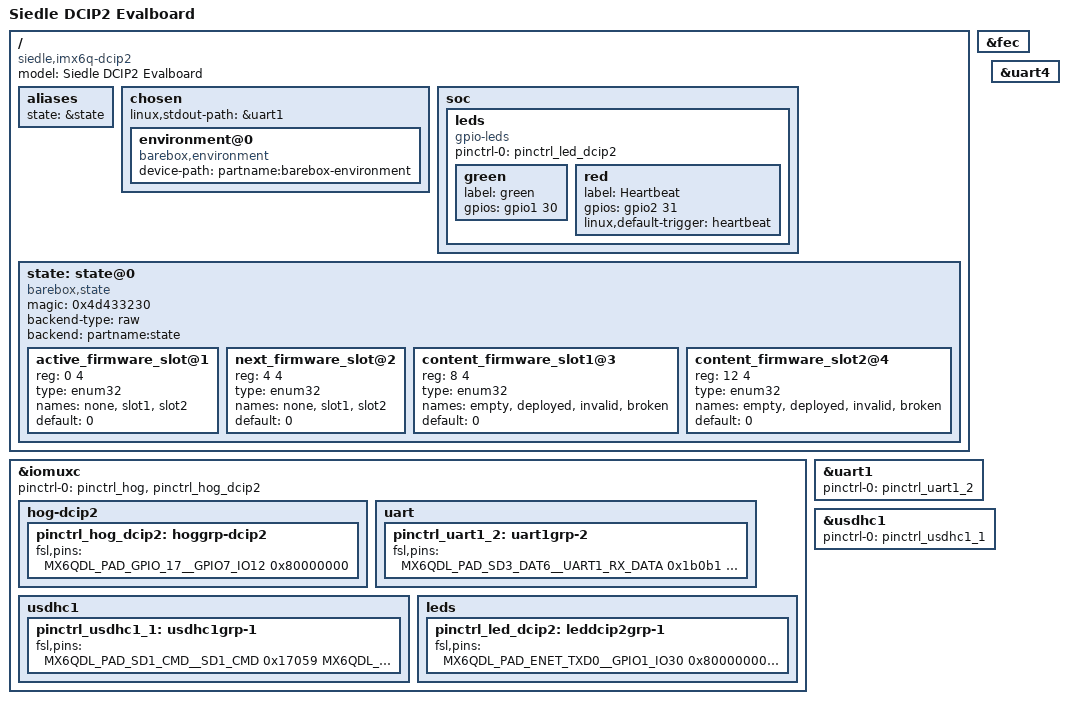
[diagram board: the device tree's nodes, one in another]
/*
 * Copyright 2013 Christian Hemp, Phytec Messtechnik GmbH
 *
 * The code contained herein is licensed under the GNU General Public
 * License. You may obtain a copy of the GNU General Public License
 * Version 2 or later at the following locations:
 *
 * http://www.opensource.org/licenses/gpl-license.html
 * http://www.gnu.org/copyleft/gpl.html
 */

/dts-v1/;
#include "imx6q-phytec-pfla02.dtsi"

/ {
	model = "Siedle DCIP2 Evalboard";
	compatible = "siedle,imx6q-dcip2", "phytec,imx6q-pfla02", "fsl,imx6q";

	aliases {
		/* make the 'state' tool happy */
		state = &state;
	};

	chosen {
		linux,stdout-path = &uart1;

		environment@0 {
			compatible = "barebox,environment";
			device-path = &flash, "partname:barebox-environment";
		};
	};

	soc {
		leds {
			pinctrl-names = "default";
			pinctrl-0 = <&pinctrl_led_dcip2>;
			compatible = "gpio-leds";

			green {
				label = "green";
				gpios = <&gpio1 30 0>;
			};

			red {
				label = "Heartbeat";
				gpios = <&gpio2 31 0>;
				linux,default-trigger = "heartbeat";
			};
		};
	};

	state: state@0 {
		magic = <0x4d433230>;
		compatible = "barebox,state";
		backend-type = "raw";
		backend = &flash, "partname:state";
		#address-cells = <1>;
		#size-cells = <1>;

		active_firmware_slot@1 {
			reg = <0 4>;
			type = "enum32";
			names = "none", "slot1", "slot2";
			default = <0>;
		};

		next_firmware_slot@2 {
			reg = <4 4>;
			type = "enum32";
			names = "none", "slot1", "slot2";
			default = <0>;
		};

		content_firmware_slot1@3 {
			/* content description of slot#1 */
			reg = <8 4>;
			type = "enum32";
			names = "empty", "deployed", "invalid", "broken";
			default = <0>;
		};

		content_firmware_slot2@4 {
			/* content description of slot#1 */
			reg = <12 4>;
			type = "enum32";
			names = "empty", "deployed", "invalid", "broken";
			default = <0>;
		};
	};
};

&fec {
	status = "okay";
};

&iomuxc {
	pinctrl-names = "default";
	pinctrl-0 = <&pinctrl_hog &pinctrl_hog_dcip2>;

	hog-dcip2 {
		pinctrl_hog_dcip2: hoggrp-dcip2 {
			fsl,pins = <
				MX6QDL_PAD_GPIO_17__GPIO7_IO12    0x80000000 /* SD slot power */
			>;
		};
	};

	uart {
		pinctrl_uart1_2: uart1grp-2 {
			fsl,pins = <
				MX6QDL_PAD_SD3_DAT6__UART1_RX_DATA 0x1b0b1
				MX6QDL_PAD_SD3_DAT7__UART1_TX_DATA 0x1b0b1
			>;
		};
	};

	usdhc1 {
		pinctrl_usdhc1_1: usdhc1grp-1 {
			fsl,pins = <
				MX6QDL_PAD_SD1_CMD__SD1_CMD    0x17059
				MX6QDL_PAD_SD1_CLK__SD1_CLK    0x10059
				MX6QDL_PAD_SD1_DAT0__SD1_DATA0 0x17059
				MX6QDL_PAD_SD1_DAT1__SD1_DATA1 0x17059
				MX6QDL_PAD_SD1_DAT2__SD1_DATA2 0x17059
				MX6QDL_PAD_SD1_DAT3__SD1_DATA3 0x17059
			>;
		};
	};

	leds {
		pinctrl_led_dcip2: leddcip2grp-1 {
			fsl,pins = <
				MX6QDL_PAD_ENET_TXD0__GPIO1_IO30	0x80000000 /* SOC Led Green */
				MX6QDL_PAD_EIM_EB3__GPIO2_IO31	0x80000000 /* SOC Led Red */
			>;
		};
	};
};

&uart1 {
	pinctrl-names = "default";
	pinctrl-0 = <&pinctrl_uart1_2>;
	status = "okay";
};

&uart4 {
	status = "okay";
};

&usdhc1 {
	pinctrl-names = "default";
	pinctrl-0 = <&pinctrl_usdhc1_1>;
	status = "okay";
};
